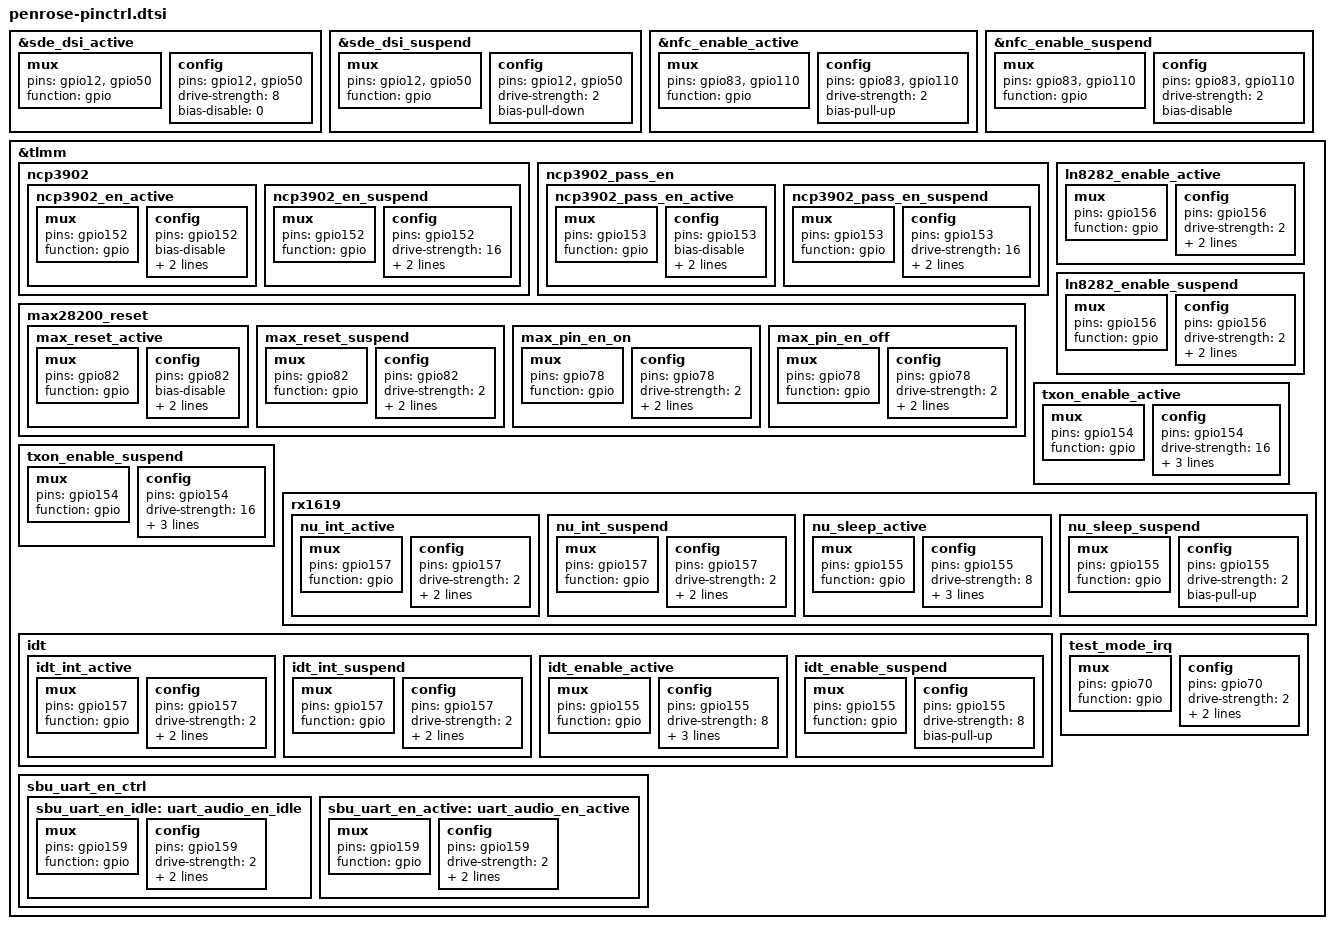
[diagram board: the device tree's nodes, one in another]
/*for penrose pinctrl */

&sde_dsi_active {
	mux {
		pins = "gpio12", "gpio50";
		function = "gpio";
	};

	config {
		pins = "gpio12", "gpio50";
		drive-strength = <8>;	/* 8 mA */
		bias-disable = <0>;   /* no pull */
	};
};

&sde_dsi_suspend {
	mux {
		pins = "gpio12", "gpio50";
		function = "gpio";
	};

	config {
		pins = "gpio12", "gpio50";
		drive-strength = <2>;	/* 2 mA */
		bias-pull-down; 		/* PULL DOWN */
	};
};

&nfc_enable_active {
	/* active state */
	mux {
		/* 83: Enable 110: Firmware */
		pins = "gpio83", "gpio110";
		function = "gpio";
	};

	config {
		pins = "gpio83", "gpio110";
		drive-strength = <2>; /* 2 MA */
		bias-pull-up;
	};
};

&nfc_enable_suspend {
	/* sleep state */
	mux {
		/* 83: Enable 110: Firmware */
		pins = "gpio83", "gpio110";
		function = "gpio";
	};

	config {
		pins = "gpio83", "gpio110";
		drive-strength = <2>; /* 2 MA */
		bias-disable;
	};
};

&tlmm {
	/* used for wire charging and otg and wirelss reverse charging features */
	ncp3902 {
		ncp3902_en_active: ncp3902_en_active {
			/* active state */
			mux {
				/* GPIO 152 is used for NCP3092 chip to enable */
				pins = "gpio152";
				function = "gpio";
			};

			config {
				pins = "gpio152";
				bias-disable; /* No PULL */
				drive-strength = <16>; /* 16 MA */
				output-low;
			};
		};

		ncp3902_en_suspend: ncp3902_en_suspend {
			/* sleep state */
			mux {
				pins = "gpio152";
				function = "gpio";
			};

			config {
				pins = "gpio152";
				drive-strength = <16>; /* 16 MA */
				bias-disable;
				output-low;
			};
		};
	};

	ncp3902_pass_en {
		ncp3902_pass_en_active: ncp3902_pass_en_active {
			/* active state */
			mux {
				pins = "gpio153";
				function = "gpio";
			};

			config {
				pins = "gpio153";
				bias-disable; /* No PULL */
				drive-strength = <16>; /* 16 MA */
				output-low;
			};
		};

		ncp3902_pass_en_suspend: ncp3902_pass_en_suspend {
			/* sleep state */
			mux {
				pins = "gpio153";
				function = "gpio";
			};

			config {
				pins = "gpio153";
				drive-strength = <16>; /* 16 MA */
				bias-disable;
				output-low;
			};
		};
	};

	max28200_reset {
		max_reset_active: max_reset_active {
			/* active state */
			mux {
				pins = "gpio82";
				function = "gpio";
			};

			config {
				pins = "gpio82";
				bias-disable;
				drive-strength = <2>; /* 16 MA */
				output-high;
			};
		};

		max_reset_suspend: max_reset_suspend {
			/* sleep state */
			mux {
				pins = "gpio82";
				function = "gpio";
			};

			config {
				pins = "gpio82";
				drive-strength = <2>; /* 16 MA */
				bias-disable;
				output-low;
			};
		};

		max_pin_en_on: max_pin_en_on {
			/* active state */
			mux {
				pins = "gpio78";
				function = "gpio";
			};

			config {
				pins = "gpio78";
				drive-strength = <2>; /* 2 MA */
				bias-disable = <0>;   /* no pull */
				input-enable;
			};
		};

		max_pin_en_off: max_pin_en_off {
			/* sleep state */
			mux {
				pins = "gpio78";
				function = "gpio";
			};

			config {
				pins = "gpio78";
				drive-strength = <2>; /* 2 MA */
				bias-disable = <0>;   /* no pull */
				input-enable;
			};
		};
	};

	ln8282_enable_active: ln8282_enable_active {
		mux {
			pins = "gpio156";
			function = "gpio";
		};

		config {
			pins = "gpio156";
			drive-strength = <2>;
			bias-pull-down;
			output-low;
		};
	};

	ln8282_enable_suspend: ln8282_enable_suspend {
		mux {
			pins = "gpio156";
			function = "gpio";
		};

		config {
			pins = "gpio156";
			drive-strength = <2>;
			bias-pull-up;
			output-high;
		};
	};

	txon_enable_active: txon_enable_active {
		/* active state */
		mux {
			pins = "gpio154";
			function = "gpio";
		};

		config {
			pins = "gpio154";
			drive-strength = <16>;
			bias-disable;
			bias-pull-down;
			output-low;
		};
	};

	txon_enable_suspend: txon_enable_suspend {
		/* sleep state */
		mux {
			pins = "gpio154";
			function = "gpio";
		};

		config {
			pins = "gpio154";
			drive-strength = <16>;
			bias-disable;
			bias-pull-down;
			output-low;
		};
	};

	rx1619 {
		nu_int_active: nu_int_active {
			/* active state */
			mux {
				pins = "gpio157";
				function = "gpio";
			};

			config {
				pins = "gpio157";
				drive-strength = <2>; /* 2 MA */
				bias-pull-up;
				input-enable;
			};
		};

		nu_int_suspend: nu_int_suspend {
			/* sleep state */
			mux {
				pins = "gpio157";
				function = "gpio";
			};

			config {
				pins = "gpio157";
				drive-strength = <2>; /* 2 MA */
				bias-pull-up;
				input-enable;
			};
		};

		nu_sleep_active: nu_sleep_active {
			/* active state */
			mux {
				pins = "gpio155";
				function = "gpio";
			};

			config {
				pins = "gpio155";
				drive-strength = <8>;
				bias-disable;
				bias-pull-down;
				output-low;
			};
		};

		nu_sleep_suspend: nu_sleep_suspend {
			/* sleep state */
			mux {
				pins = "gpio155";
				function = "gpio";
			};

			config {
				pins = "gpio155";
				drive-strength = <2>;
				bias-pull-up;
			};
		};
	};

	idt {
		idt_int_active: idt_int_active {
			/* active state */
			mux {
				pins = "gpio157";
				function = "gpio";
			};

			config {
				pins = "gpio157";
				drive-strength = <2>; /* 2 MA */
				bias-pull-up;
				input-enable;
			};
		};

		idt_int_suspend: idt_int_suspend {
			/* sleep state */
			mux {
				pins = "gpio157";
				function = "gpio";
			};

			config {
				pins = "gpio157";
				drive-strength = <2>; /* 2 MA */
				bias-pull-up;
				input-enable;
			};
		};

		idt_enable_active: idt_enable_active {
			/* active state */
			mux {
				pins = "gpio155";
				function = "gpio";
			};

			config {
				pins = "gpio155";
				drive-strength = <8>;
				bias-disable;
				bias-pull-down;
				output-low;
			};
		};

		idt_enable_suspend: idt_enable_suspend {
			/* sleep state */
			mux {
				pins = "gpio155";
				function = "gpio";
			};

			config {
				pins = "gpio155";
				drive-strength = <8>;
				bias-pull-up;
			};
		};

	};

	sbu_uart_en_ctrl {
		sbu_uart_en_idle: uart_audio_en_idle {
			mux {
				pins = "gpio159";
				function = "gpio";
			};
			config {
				pins = "gpio159";
				drive-strength = <2>;
				bias-pull-down;
				output-low;
			};
		};

		sbu_uart_en_active: uart_audio_en_active {
			mux {
				pins = "gpio159";
				function = "gpio";
			};
			config {
				pins = "gpio159";
				drive-strength = <2>;
				bias-disable;
				output-high;
			};
		};
	};

	test_mode_irq: test_mode_irq {
		mux {
			pins = "gpio70";
			function = "gpio";
		};

		config {
			pins = "gpio70";
			drive-strength = <2>;
			bias-pull-up;
			input-enable;
		};
	};
};
